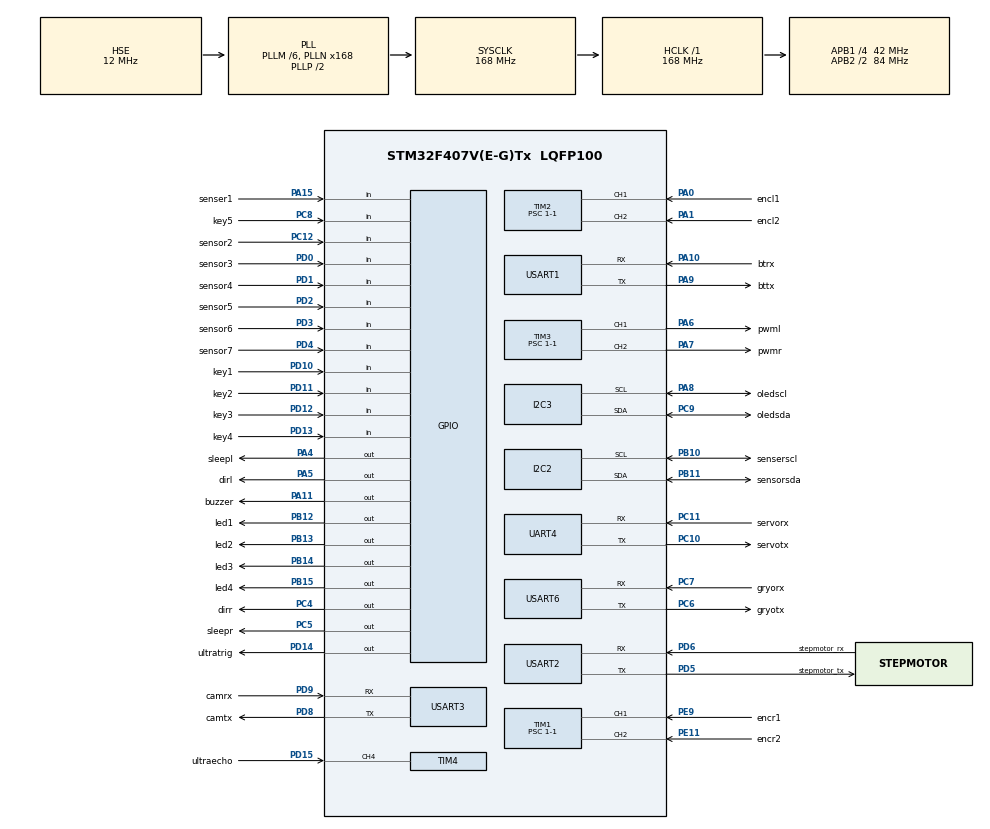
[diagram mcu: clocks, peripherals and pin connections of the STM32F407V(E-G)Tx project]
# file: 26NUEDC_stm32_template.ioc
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Dma.I2C2_RX.7.Direction=DMA_PERIPH_TO_MEMORY
Dma.I2C2_RX.7.FIFOMode=DMA_FIFOMODE_DISABLE
Dma.I2C2_RX.7.Instance=DMA1_Stream2
Dma.I2C2_RX.7.MemDataAlignment=DMA_MDATAALIGN_BYTE
Dma.I2C2_RX.7.MemInc=DMA_MINC_ENABLE
Dma.I2C2_RX.7.Mode=DMA_NORMAL
Dma.I2C2_RX.7.PeriphDataAlignment=DMA_PDATAALIGN_BYTE
Dma.I2C2_RX.7.PeriphInc=DMA_PINC_DISABLE
Dma.I2C2_RX.7.Priority=DMA_PRIORITY_LOW
Dma.I2C2_TX.6.Direction=DMA_MEMORY_TO_PERIPH
Dma.I2C2_TX.6.FIFOMode=DMA_FIFOMODE_DISABLE
Dma.I2C2_TX.6.Instance=DMA1_Stream7
Dma.I2C2_TX.6.MemDataAlignment=DMA_MDATAALIGN_BYTE
Dma.I2C2_TX.6.MemInc=DMA_MINC_ENABLE
Dma.I2C2_TX.6.Mode=DMA_NORMAL
Dma.I2C2_TX.6.PeriphDataAlignment=DMA_PDATAALIGN_BYTE
Dma.I2C2_TX.6.PeriphInc=DMA_PINC_DISABLE
Dma.I2C2_TX.6.Priority=DMA_PRIORITY_HIGH
Dma.Request0=USART1_RX
Dma.Request1=USART1_TX
Dma.Request2=USART3_RX
Dma.Request3=USART3_TX
Dma.Request4=USART6_RX
Dma.Request5=USART6_TX
Dma.Request6=I2C2_TX
Dma.Request7=I2C2_RX
Dma.Request8=USART2_RX
Dma.Request9=USART2_TX
Dma.USART1_RX.0.Direction=DMA_PERIPH_TO_MEMORY
Dma.USART1_RX.0.FIFOMode=DMA_FIFOMODE_DISABLE
Dma.USART1_RX.0.Instance=DMA2_Stream2
Dma.USART1_RX.0.MemDataAlignment=DMA_MDATAALIGN_BYTE
Dma.USART1_RX.0.MemInc=DMA_MINC_ENABLE
Dma.USART1_RX.0.Mode=DMA_NORMAL
Dma.USART1_RX.0.PeriphDataAlignment=DMA_PDATAALIGN_BYTE
Dma.USART1_RX.0.PeriphInc=DMA_PINC_DISABLE
Dma.USART1_RX.0.Priority=DMA_PRIORITY_MEDIUM
Dma.USART1_TX.1.Direction=DMA_MEMORY_TO_PERIPH
Dma.USART1_TX.1.FIFOMode=DMA_FIFOMODE_DISABLE
Dma.USART1_TX.1.Instance=DMA2_Stream7
Dma.USART1_TX.1.MemDataAlignment=DMA_MDATAALIGN_BYTE
Dma.USART1_TX.1.MemInc=DMA_MINC_ENABLE
Dma.USART1_TX.1.Mode=DMA_NORMAL
Dma.USART1_TX.1.PeriphDataAlignment=DMA_PDATAALIGN_BYTE
Dma.USART1_TX.1.PeriphInc=DMA_PINC_DISABLE
Dma.USART1_TX.1.Priority=DMA_PRIORITY_MEDIUM
Dma.USART2_RX.8.Direction=DMA_PERIPH_TO_MEMORY
Dma.USART2_RX.8.FIFOMode=DMA_FIFOMODE_DISABLE
Dma.USART2_RX.8.Instance=DMA1_Stream5
Dma.USART2_RX.8.MemDataAlignment=DMA_MDATAALIGN_BYTE
Dma.USART2_RX.8.MemInc=DMA_MINC_ENABLE
Dma.USART2_RX.8.Mode=DMA_NORMAL
Dma.USART2_RX.8.PeriphDataAlignment=DMA_PDATAALIGN_BYTE
Dma.USART2_RX.8.PeriphInc=DMA_PINC_DISABLE
Dma.USART2_RX.8.Priority=DMA_PRIORITY_HIGH
Dma.USART2_TX.9.Direction=DMA_MEMORY_TO_PERIPH
Dma.USART2_TX.9.FIFOMode=DMA_FIFOMODE_DISABLE
Dma.USART2_TX.9.Instance=DMA1_Stream6
Dma.USART2_TX.9.MemDataAlignment=DMA_MDATAALIGN_BYTE
Dma.USART2_TX.9.MemInc=DMA_MINC_ENABLE
Dma.USART2_TX.9.Mode=DMA_NORMAL
Dma.USART2_TX.9.PeriphDataAlignment=DMA_PDATAALIGN_BYTE
Dma.USART2_TX.9.PeriphInc=DMA_PINC_DISABLE
Dma.USART2_TX.9.Priority=DMA_PRIORITY_HIGH
Dma.USART3_RX.2.Direction=DMA_PERIPH_TO_MEMORY
Dma.USART3_RX.2.FIFOMode=DMA_FIFOMODE_DISABLE
Dma.USART3_RX.2.Instance=DMA1_Stream1
Dma.USART3_RX.2.MemDataAlignment=DMA_MDATAALIGN_BYTE
Dma.USART3_RX.2.MemInc=DMA_MINC_ENABLE
Dma.USART3_RX.2.Mode=DMA_NORMAL
Dma.USART3_RX.2.PeriphDataAlignment=DMA_PDATAALIGN_BYTE
Dma.USART3_RX.2.PeriphInc=DMA_PINC_DISABLE
Dma.USART3_RX.2.Priority=DMA_PRIORITY_HIGH
Dma.USART3_TX.3.Direction=DMA_MEMORY_TO_PERIPH
Dma.USART3_TX.3.FIFOMode=DMA_FIFOMODE_DISABLE
Dma.USART3_TX.3.Instance=DMA1_Stream3
Dma.USART3_TX.3.MemDataAlignment=DMA_MDATAALIGN_BYTE
Dma.USART3_TX.3.MemInc=DMA_MINC_ENABLE
Dma.USART3_TX.3.Mode=DMA_NORMAL
Dma.USART3_TX.3.PeriphDataAlignment=DMA_PDATAALIGN_BYTE
Dma.USART3_TX.3.PeriphInc=DMA_PINC_DISABLE
Dma.USART3_TX.3.Priority=DMA_PRIORITY_HIGH
Dma.USART6_RX.4.Direction=DMA_PERIPH_TO_MEMORY
Dma.USART6_RX.4.FIFOMode=DMA_FIFOMODE_DISABLE
Dma.USART6_RX.4.Instance=DMA2_Stream1
Dma.USART6_RX.4.MemDataAlignment=DMA_MDATAALIGN_BYTE
Dma.USART6_RX.4.MemInc=DMA_MINC_ENABLE
Dma.USART6_RX.4.Mode=DMA_NORMAL
Dma.USART6_RX.4.PeriphDataAlignment=DMA_PDATAALIGN_BYTE
Dma.USART6_RX.4.PeriphInc=DMA_PINC_DISABLE
Dma.USART6_RX.4.Priority=DMA_PRIORITY_VERY_HIGH
Dma.USART6_TX.5.Direction=DMA_MEMORY_TO_PERIPH
Dma.USART6_TX.5.FIFOMode=DMA_FIFOMODE_DISABLE
Dma.USART6_TX.5.Instance=DMA2_Stream6
Dma.USART6_TX.5.MemDataAlignment=DMA_MDATAALIGN_BYTE
Dma.USART6_TX.5.MemInc=DMA_MINC_ENABLE
Dma.USART6_TX.5.Mode=DMA_NORMAL
Dma.USART6_TX.5.PeriphDataAlignment=DMA_PDATAALIGN_BYTE
Dma.USART6_TX.5.PeriphInc=DMA_PINC_DISABLE
Dma.USART6_TX.5.Priority=DMA_PRIORITY_VERY_HIGH
IWDG.Prescaler=IWDG_PRESCALER_32
IWDG.Reload=500
Mcu.Family=STM32F4
Mcu.Name=STM32F407V(E-G)Tx
Mcu.Package=LQFP100
NVIC.DMA1_Stream1_IRQn=true\:0\:0\:false\:false\:true\:false\:true\:true
NVIC.DMA1_Stream2_IRQn=true\:0\:0\:false\:false\:true\:false\:true\:true
NVIC.DMA1_Stream3_IRQn=true\:0\:0\:false\:false\:true\:false\:true\:true
NVIC.DMA1_Stream5_IRQn=true\:0\:0\:false\:false\:true\:false\:true\:true
NVIC.DMA1_Stream6_IRQn=true\:0\:0\:false\:false\:true\:false\:true\:true
NVIC.DMA1_Stream7_IRQn=true\:0\:0\:false\:false\:true\:false\:true\:true
NVIC.DMA2_Stream1_IRQn=true\:0\:0\:false\:false\:true\:false\:true\:true
NVIC.DMA2_Stream2_IRQn=true\:0\:0\:false\:false\:true\:false\:true\:true
NVIC.DMA2_Stream6_IRQn=true\:0\:0\:false\:false\:true\:false\:true\:true
NVIC.DMA2_Stream7_IRQn=true\:0\:0\:false\:false\:true\:false\:true\:true
NVIC.I2C2_ER_IRQn=true\:2\:1\:true\:false\:true\:true\:true\:true
NVIC.I2C2_EV_IRQn=true\:2\:1\:true\:false\:true\:true\:true\:true
NVIC.I2C3_ER_IRQn=true\:2\:2\:true\:false\:true\:true\:true\:true
NVIC.I2C3_EV_IRQn=true\:2\:2\:true\:false\:true\:true\:true\:true
NVIC.PriorityGroup=NVIC_PRIORITYGROUP_2
NVIC.TIM1_UP_TIM10_IRQn=true\:3\:0\:true\:false\:true\:true\:true\:true
NVIC.TIM2_IRQn=true\:3\:0\:true\:false\:true\:true\:true\:true
NVIC.TIM4_IRQn=true\:2\:0\:true\:false\:true\:true\:true\:true
NVIC.TIM6_DAC_IRQn=true\:0\:0\:false\:false\:true\:true\:true\:true
NVIC.UART4_IRQn=true\:1\:2\:true\:false\:true\:true\:true\:true
NVIC.USART1_IRQn=true\:1\:3\:true\:false\:true\:true\:true\:true
NVIC.USART2_IRQn=true\:1\:2\:true\:false\:true\:true\:true\:true
NVIC.USART3_IRQn=true\:1\:1\:true\:false\:true\:true\:true\:true
NVIC.USART6_IRQn=true\:1\:0\:true\:false\:true\:true\:true\:true
PA0-WKUP.GPIO_Label=encl1
PA0-WKUP.Signal=S_TIM2_CH1_ETR
PA1.GPIO_Label=encl2
PA1.Signal=S_TIM2_CH2
PA10.GPIO_Label=btrx
PA10.Mode=Asynchronous
PA10.Signal=USART1_RX
PA11.GPIO_Label=buzzer
PA11.GPIO_PuPd=GPIO_PULLUP
PA11.Signal=GPIO_Output
PA13.Mode=Serial_Wire
PA13.Signal=SYS_JTMS-SWDIO
PA14.Mode=Serial_Wire
PA14.Signal=SYS_JTCK-SWCLK
PA15.GPIO_Label=senser1
PA15.Signal=GPIO_Input
PA4.GPIO_Label=sleepl
PA4.PinState=GPIO_PIN_RESET
PA4.Signal=GPIO_Output
PA5.GPIO_Label=dirl
PA5.Signal=GPIO_Output
PA6.GPIO_Label=pwml
PA6.Signal=S_TIM3_CH1
PA7.GPIO_Label=pwmr
PA7.Signal=S_TIM3_CH2
PA8.GPIO_Label=oledscl
PA8.Mode=I2C
PA8.Signal=I2C3_SCL
PA9.GPIO_Label=bttx
PA9.Mode=Asynchronous
PA9.Signal=USART1_TX
PB10.GPIO_Label=senserscl
PB10.Mode=I2C
PB10.Signal=I2C2_SCL
PB11.GPIO_Label=sensorsda
PB11.Mode=I2C
PB11.Signal=I2C2_SDA
PB12.GPIO_Label=led1
PB12.Signal=GPIO_Output
PB13.GPIO_Label=led2
PB13.Signal=GPIO_Output
PB14.GPIO_Label=led3
PB14.Signal=GPIO_Output
PB15.GPIO_Label=led4
PB15.Signal=GPIO_Output
PC10.GPIO_Label=servotx
PC10.Mode=Asynchronous
PC10.Signal=UART4_TX
PC11.GPIO_Label=servorx
PC11.Mode=Asynchronous
PC11.Signal=UART4_RX
PC12.GPIO_Label=sensor2
PC12.Signal=GPIO_Input
PC4.GPIO_Label=dirr
PC4.Signal=GPIO_Output
PC5.GPIO_Label=sleepr
PC5.PinState=GPIO_PIN_RESET
PC5.Signal=GPIO_Output
PC6.GPIO_Label=gryotx
PC6.Mode=Asynchronous
PC6.Signal=USART6_TX
PC7.GPIO_Label=gryorx
PC7.Mode=Asynchronous
PC7.Signal=USART6_RX
PC8.GPIO_Label=key5
PC8.GPIO_PuPd=GPIO_PULLUP
PC8.Signal=GPIO_Input
PC9.GPIO_Label=oledsda
PC9.Mode=I2C
PC9.Signal=I2C3_SDA
PD0.GPIO_Label=sensor3
PD0.Signal=GPIO_Input
PD1.GPIO_Label=sensor4
PD1.Signal=GPIO_Input
PD10.GPIO_Label=key1
PD10.GPIO_PuPd=GPIO_PULLUP
PD10.Signal=GPIO_Input
PD11.GPIO_Label=key2
PD11.GPIO_PuPd=GPIO_PULLUP
PD11.Signal=GPIO_Input
PD12.GPIO_Label=key3
PD12.GPIO_PuPd=GPIO_PULLUP
PD12.Signal=GPIO_Input
PD13.GPIO_Label=key4
PD13.GPIO_PuPd=GPIO_PULLUP
PD13.Signal=GPIO_Input
PD14.GPIO_Label=ultratrig
PD14.Signal=GPIO_Output
PD15.GPIO_Label=ultraecho
PD15.Signal=S_TIM4_CH4
PD2.GPIO_Label=sensor5
PD2.Signal=GPIO_Input
PD3.GPIO_Label=sensor6
PD3.Signal=GPIO_Input
PD4.GPIO_Label=sensor7
PD4.Signal=GPIO_Input
PD5.GPIO_Label=stepmotor_tx
PD5.Mode=Asynchronous
PD5.Signal=USART2_TX
PD6.GPIO_Label=stepmotor_rx
PD6.Mode=Asynchronous
PD6.Signal=USART2_RX
PD8.GPIO_Label=camtx
PD8.Mode=Asynchronous
PD8.Signal=USART3_TX
PD9.GPIO_Label=camrx
PD9.Mode=Asynchronous
PD9.Signal=USART3_RX
PE11.GPIO_Label=encr2
PE11.Signal=S_TIM1_CH2
PE9.GPIO_Label=encr1
PE9.Signal=S_TIM1_CH1
PH0-OSC_IN.Mode=HSE-External-Oscillator
PH0-OSC_IN.Signal=RCC_OSC_IN
PH1-OSC_OUT.Mode=HSE-External-Oscillator
PH1-OSC_OUT.Signal=RCC_OSC_OUT
ProjectManager.HeapSize=0x200
ProjectManager.StackSize=0x400
ProjectManager.TargetToolchain=CMake
RCC.48MHZClocksFreq_Value=84000000
RCC.AHBFreq_Value=168000000
RCC.APB1CLKDivider=RCC_HCLK_DIV4
RCC.APB1Freq_Value=42000000
RCC.APB1TimFreq_Value=84000000
RCC.APB2CLKDivider=RCC_HCLK_DIV2
RCC.APB2Freq_Value=84000000
RCC.APB2TimFreq_Value=168000000
RCC.CortexFreq_Value=168000000
RCC.HCLKFreq_Value=168000000
RCC.HSE_VALUE=12000000
RCC.HSI_VALUE=16000000
RCC.LSE_VALUE=32768
RCC.PLLM=6
RCC.PLLN=168
RCC.PLLSourceVirtual=RCC_PLLSOURCE_HSE
RCC.SYSCLKFreq_VALUE=168000000
RCC.SYSCLKSource=RCC_SYSCLKSOURCE_PLLCLK
RCC.VCOOutputFreq_Value=336000000
SH.S_TIM1_CH1.0=TIM1_CH1,Encoder_Interface
SH.S_TIM1_CH2.0=TIM1_CH2,Encoder_Interface
SH.S_TIM2_CH1_ETR.0=TIM2_CH1,Encoder_Interface
SH.S_TIM2_CH2.0=TIM2_CH2,Encoder_Interface
SH.S_TIM3_CH1.0=TIM3_CH1,PWM Generation1 CH1
SH.S_TIM3_CH2.0=TIM3_CH2,PWM Generation2 CH2
SH.S_TIM4_CH4.0=TIM4_CH4,Input_Capture4_from_TI4
TIM1.AutoReloadPreload=TIM_AUTORELOAD_PRELOAD_ENABLE
TIM1.EncoderMode=TIM_ENCODERMODE_TI12
TIM1.IC1Filter=0x6
TIM1.IC2Filter=0x6
TIM1.Period=65536-1
TIM1.Prescaler=1-1
TIM2.AutoReloadPreload=TIM_AUTORELOAD_PRELOAD_ENABLE
TIM2.EncoderMode=TIM_ENCODERMODE_TI12
TIM2.IC1Filter=0x6
TIM2.IC2Filter=0x6
TIM2.Prescaler=1-1
TIM3.AutoReloadPreload=TIM_AUTORELOAD_PRELOAD_ENABLE
TIM3.Channel-PWM\ Generation1\ CH1=TIM_CHANNEL_1
TIM3.Channel-PWM\ Generation2\ CH2=TIM_CHANNEL_2
TIM3.Period=4199
TIM3.Prescaler=1-1
TIM4.AutoReloadPreload=TIM_AUTORELOAD_PRELOAD_ENABLE
TIM4.Channel-Input_Capture4_from_TI4=TIM_CHANNEL_4
TIM4.ICPolarity_CH4=TIM_INPUTCHANNELPOLARITY_RISING
TIM4.Prescaler=84-1
TIM6.AutoReloadPreload=TIM_AUTORELOAD_PRELOAD_ENABLE
TIM6.Period=100-1
TIM6.Prescaler=840-1
UART4.VirtualMode=Asynchronous
USART1.VirtualMode=VM_ASYNC
USART2.VirtualMode=VM_ASYNC
USART3.VirtualMode=VM_ASYNC
USART6.VirtualMode=VM_ASYNC
VP_IWDG_VS_IWDG.Mode=IWDG_Activate
VP_TIM6_VS_ClockSourceINT.Mode=Enable_Timer
board=custom

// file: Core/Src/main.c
/* USER CODE BEGIN Header */
/**
  ******************************************************************************
  * @file           : main.c
  * @brief          : Main program body
  ******************************************************************************
  * @attention
  *
  * Copyright (c) 2026 STMicroelectronics.
  * All rights reserved.
  *
  * This software is licensed under terms that can be found in the LICENSE file
  * in the root directory of this software component.
  * If no LICENSE file comes with this software, it is provided AS-IS.
  *
  ******************************************************************************
  */
/* USER CODE END Header */
#include "main.h"
#include "dma.h"
#include "i2c.h"
#include "iwdg.h"
#include "tim.h"
#include "usart.h"
#include "gpio.h"

/* USER CODE BEGIN Includes */
#include "app.h"
/* USER CODE END Includes */

void SystemClock_Config(void);

int main(void)
{

  /* MCU Configuration--------------------------------------------------------*/

  /* Reset of all peripherals, Initializes the Flash interface and the Systick. */
  HAL_Init();

  /* Configure the system clock */
  SystemClock_Config();

  /* Initialize all configured peripherals */
  MX_GPIO_Init();
  MX_DMA_Init();
  MX_TIM1_Init();
  MX_TIM2_Init();
  MX_TIM3_Init();
  MX_TIM6_Init();
  MX_USART1_UART_Init();
  MX_USART3_UART_Init();
  MX_USART6_UART_Init();
  MX_I2C2_Init();
  MX_I2C3_Init();
  MX_TIM4_Init();
  MX_UART4_Init();
  MX_USART2_UART_Init();
  MX_IWDG_Init();
  /* USER CODE BEGIN 2 */
  if (HAL_TIM_Base_Start_IT(&htim6) != HAL_OK) {
    Error_Handler();
  }
  if (app_init() != STATUS_OK) {
    Error_Handler();
  }
  /* USER CODE END 2 */

  /* Infinite loop */
  while (1)
  {

    /* USER CODE BEGIN 3 */
    app_run_once();
  }
  /* USER CODE END 3 */
}

void SystemClock_Config(void)
{
  RCC_OscInitTypeDef RCC_OscInitStruct = {0};
  RCC_ClkInitTypeDef RCC_ClkInitStruct = {0};

  /** Configure the main internal regulator output voltage
  */
  __HAL_RCC_PWR_CLK_ENABLE();
  __HAL_PWR_VOLTAGESCALING_CONFIG(PWR_REGULATOR_VOLTAGE_SCALE1);

  /** Initializes the RCC Oscillators according to the specified parameters
  * in the RCC_OscInitTypeDef structure.
  */
  RCC_OscInitStruct.OscillatorType = RCC_OSCILLATORTYPE_LSI|RCC_OSCILLATORTYPE_HSE;
  RCC_OscInitStruct.HSEState = RCC_HSE_ON;
  RCC_OscInitStruct.LSIState = RCC_LSI_ON;
  RCC_OscInitStruct.PLL.PLLState = RCC_PLL_ON;
  RCC_OscInitStruct.PLL.PLLSource = RCC_PLLSOURCE_HSE;
  RCC_OscInitStruct.PLL.PLLM = 6;
  RCC_OscInitStruct.PLL.PLLN = 168;
  RCC_OscInitStruct.PLL.PLLP = RCC_PLLP_DIV2;
  RCC_OscInitStruct.PLL.PLLQ = 4;
  if (HAL_RCC_OscConfig(&RCC_OscInitStruct) != HAL_OK)
  {
    Error_Handler();
  }

  /** Initializes the CPU, AHB and APB buses clocks
  */
  RCC_ClkInitStruct.ClockType = RCC_CLOCKTYPE_HCLK|RCC_CLOCKTYPE_SYSCLK
                              |RCC_CLOCKTYPE_PCLK1|RCC_CLOCKTYPE_PCLK2;
  RCC_ClkInitStruct.SYSCLKSource = RCC_SYSCLKSOURCE_PLLCLK;
  RCC_ClkInitStruct.AHBCLKDivider = RCC_SYSCLK_DIV1;
  RCC_ClkInitStruct.APB1CLKDivider = RCC_HCLK_DIV4;
  RCC_ClkInitStruct.APB2CLKDivider = RCC_HCLK_DIV2;

  if (HAL_RCC_ClockConfig(&RCC_ClkInitStruct, FLASH_LATENCY_5) != HAL_OK)
  {
    Error_Handler();
  }
}

void Error_Handler(void)
{
  __disable_irq();
  while (1)
  {
  }
}
#ifdef USE_FULL_ASSERT
/**
  * @brief  Reports the name of the source file and the source line number
  *         where the assert_param error has occurred.
  * @param  file: pointer to the source file name
  * @param  line: assert_param error line source number
  * @retval None
  */
void assert_failed(uint8_t *file, uint32_t line)
{
  /* USER CODE BEGIN 6 */
  /* User can add his own implementation to report the file name and line number,
     ex: printf("Wrong parameters value: file %s on line %d\r\n", file, line) */
  (void)file;
  (void)line;
  /* USER CODE END 6 */
}
#endif /* USE_FULL_ASSERT */
